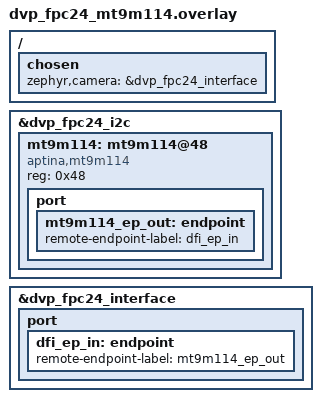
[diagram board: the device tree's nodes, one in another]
/*
 * Copyright 2024 NXP
 *
 * SPDX-License-Identifier: Apache-2.0
 */

/{
	chosen {
		zephyr,camera = &dvp_fpc24_interface;
	};
};

&dvp_fpc24_i2c {
	mt9m114: mt9m114@48 {
		compatible = "aptina,mt9m114";
		reg = <0x48>;

		port {
			mt9m114_ep_out: endpoint {
				remote-endpoint-label = "dfi_ep_in";
			};
		};
	};
};

&dvp_fpc24_interface {
	status = "okay";

	port {
		dfi_ep_in: endpoint {
			remote-endpoint-label = "mt9m114_ep_out";
		};
	};
};
